# apollo3c register map
Vendor: Ambiq Micro; Series: Apollo; File version: 1.0
CPU: CM4 r1p0, little endian, MPU, FPU, 3 interrupt priority bits
Registers are 32-bit, read-write, reset 0x0 unless marked. A register's access mark holds for its fields unless they carry their own. Offsets are from the block's base; [hi:lo] are bit positions; lines under a group give offsets from that group; {n}, {i} and the like mark numbered series; 'fields as' and 'values as' point back to an identical list.

## GPIO (part 2 of 2) — General Purpose IO
Base 0x40010000
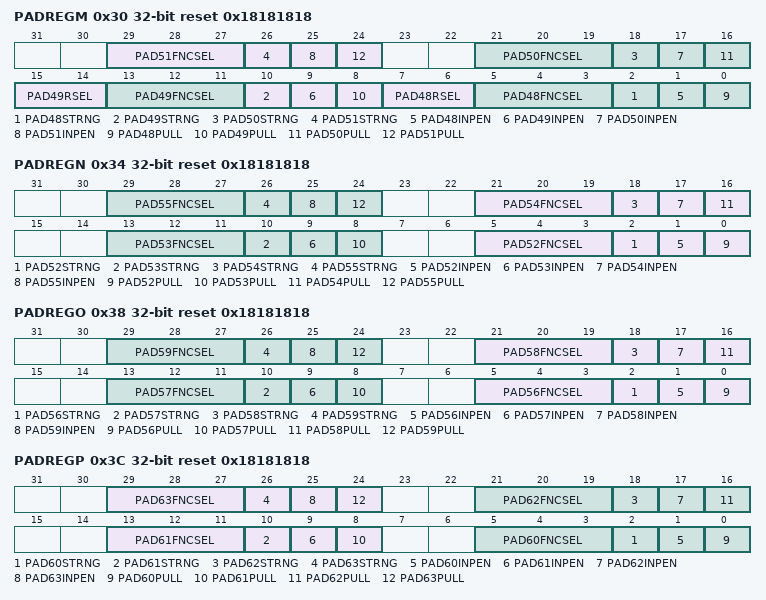
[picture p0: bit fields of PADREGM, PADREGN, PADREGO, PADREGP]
0x30 PADREGM reset 0x18181818 — Pad Configuration Register M (Pads 48-51)
  [29:27] PAD51FNCSEL — Pad 51 function select
    0=MSPI1_0 (Configure as the MSPI1 0 signal); 1=NCE51 (IOM/MSPI nCE group 51); 2=CT1 (CTIMER connection 1); 3=GPIO51 (Configure as GPIO51)
  [8n-382] PAD{n}STRNG (n=48..51) — Pad {n} drive strength
    0=LOW (Low drive strength); 1=HIGH (High drive strength)
  [8n-383] PAD{n}INPEN (n=48..51) — Pad {n} input enable
    0=DIS (Pad input disabled); 1=EN (Pad input enabled)
  [8n-384] PAD{n}PULL (n=48..51) — Pad {n} pullup enable
    0=DIS (Pullup disabled); 1=EN (Pullup enabled)
  [21:19] PAD50FNCSEL — Pad 50 function select
    0=SWO (Configure as the SWO output); 1=NCE50 (IOM/MSPI nCE group 50); 2=CT0 (CTIMER connection 0); 3=GPIO50 (Configure as GPIO50); 4=UART0TX (Configure as the UART0 TX output); 5=UART0RX (Configure as the UART0 RX input); 6=UART1TX (Configure as the UART1 TX output); 7=UART1RX (Configure as the UART1 RX input)
  [15:14] PAD49RSEL — Pad 49 pullup resistor selection.
    0=PULL1_5K (Pullup is ~1.5 KOhms); 1=PULL6K (Pullup is ~6 KOhms); 2=PULL12K (Pullup is ~12 KOhms); 3=PULL24K (Pullup is ~24 KOhms)
  [13:11] PAD49FNCSEL — Pad 49 function select
    0=UART0RX (Configure as the UART0 RX input signal); 1=NCE49 (IOM/MSPPI nCE group 49); 2=CT30 (CTIMER connection 30); 3=GPIO49 (Configure as GPIO49); 4=M5SDAWIR3 (Configure as the IOMSTR5 I2C SDA or SPI WIR3 signal); 5=M5MISO (Configure as the IOMSTR5 SPI MISO input signal)
  [7:6] PAD48RSEL — Pad 48 pullup resistor selection.
    values as PAD49RSEL
  [5:3] PAD48FNCSEL — Pad 48 function select
    0=UART0TX (Configure as the UART0 TX output signal); 1=NCE48 (IOM/MSPI nCE group 48); 2=CT28 (CTIMER conenction 28); 3=GPIO48 (Configure as GPIO48); 4=M5SCL (Configure as the IOMSTR5 I2C SCL clock I/O signal); 5=M5SCK (Configure as the IOMSTR5 SPI SCK output)
0x34 PADREGN reset 0x18181818 — Pad Configuration Register N (Pads 52-55)
  [8n-411:8n-413] PAD{n}FNCSEL (n=52..55) — Pad {n} function select
    0=MSPI1_{n-51} (Configure as the MSPI1 {n-51} signal); 1=NCE{n} (IOM/MSPI nCE group {n}); 2=CT{n-50} (CTIMER connection {n-50}); 3=GPIO{n} (Configure as GPIO{n})
  [8n-414] PAD{n}STRNG (n=52..55) — Pad {n} drive strength
    0=LOW (Low drive strength); 1=HIGH (High drive strength)
  [8n-415] PAD{n}INPEN (n=52..55) — Pad {n} input enable
    0=DIS (Pad input disabled); 1=EN (Pad input enabled)
  [8n-416] PAD{n}PULL (n=52..55) — Pad {n} pullup enable
    0=DIS (Pullup disabled); 1=EN (Pullup enabled)
0x38 PADREGO reset 0x18181818 — Pad Configuration Register O (Pads 56-59)
  [8n-443:8n-445] PAD{n}FNCSEL (n=56..59) — Pad {n} function select
    values as PADREGN.PAD52FNCSEL
  [8n-446] PAD{n}STRNG (n=56..59) — Pad {n} drive strength
    0=LOW (Low drive strength); 1=HIGH (High drive strength)
  [8n-447] PAD{n}INPEN (n=56..59) — Pad {n} input enable
    0=DIS (Pad input disabled); 1=EN (Pad input enabled)
  [8n-448] PAD{n}PULL (n=56..59) — Pad {n} pullup enable
    0=DIS (Pullup disabled); 1=EN (Pullup enabled)
0x3C PADREGP reset 0x18181818 — Pad Configuration Register P (Pads 60-63)
  [29:27] PAD63FNCSEL — Pad 63 function select
    0=SWO (Configure as the SWO output); 1=NCE63 (IOM/MSPI nCE group 63); 2=CT13 (CTIMER connection 13); 3=GPIO63 (Configure as GPIO63); 4=UART0TX (Configure as the UART0 TX output); 5=UART0RX (Configure as the UART0 RX input); 6=UART1TX (Configure as the UART1 TX output); 7=UART1RX (Configure as the UART1 RX input)
  [8n-478] PAD{n}STRNG (n=60..63) — Pad {n} drive strength
    0=LOW (Low drive strength); 1=HIGH (High drive strength)
  [8n-479] PAD{n}INPEN (n=60..63) — Pad {n} input enable
    0=DIS (Pad input disabled); 1=EN (Pad input enabled)
  [8n-480] PAD{n}PULL (n=60..63) — Pad {n} pullup enable
    0=DIS (Pullup disabled); 1=EN (Pullup enabled)
  [21:19] PAD62FNCSEL — Pad 62 function select
    0=SWO (Configure as the SWO output); 1=NCE62 (IOM/MSPI nCE group 62); 2=CT12 (CTIMER connection 12); 3=GPIO62 (Configure as GPIO62); 4=UA0CTS (Configure as the UART0 CTS input); 5=UA0RTS (Configure as the UART0 RTS output); 6=UA1CTS (Configure as the UART1 CTS input); 7=UA1RTS (Configure as the UART1 RTS output)
  [13:11] PAD61FNCSEL — Pad 61 function select
    0=SWO (Configure as the SWO output); 1=NCE61 (IOM/MSPI nCE group 61); 2=CT11 (CTIMER connection 11); 3=GPIO61 (Configure as GPIO61); 4=UART0TX (Configure as the UART0 TX output); 5=UART0RX (Configure as the UART0 RX input); 6=UART1TX (Configure as the UART1 TX output); 7=UART1RX (Configure as the UART1 RX input)
  [5:3] PAD60FNCSEL — Pad 60 function select
    0=MSPI1_9 (Configure as the MSPI1 9 signal); 1=NCE60 (IOM/MSPI nCE group 60); 2=CT10 (CTIMER connection 10); 3=GPIO60 (Configure as GPIO60)
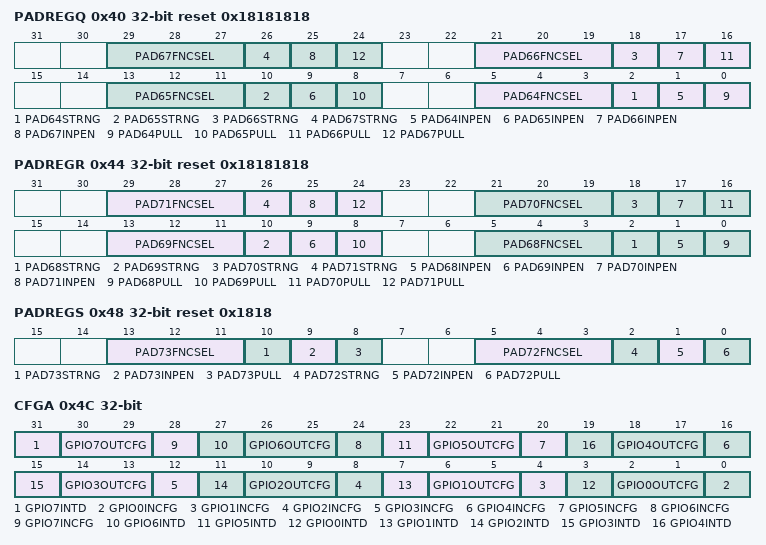
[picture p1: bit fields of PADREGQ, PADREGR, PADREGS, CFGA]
0x40 PADREGQ reset 0x18181818 — Pad Configuration Register Q (Pads 64-67)
  [8n-507:8n-509] PAD{n}FNCSEL (n=64..67) — Pad {n} function select
    0=MSPI2_{n-64} (Configure as the MSPI2 {n-64} signal); 1=NCE{n} (IOM/MSPI nCE group {n}); 2=CT{n-50} (CTIMER connection {n-50}); 3=GPIO{n} (Configure as GPIO{n})
  [8n-510] PAD{n}STRNG (n=64..67) — Pad {n} drive strength
    0=LOW (Low drive strength); 1=HIGH (High drive strength)
  [8n-511] PAD{n}INPEN (n=64..67) — Pad {n} input enable
    0=DIS (Pad input disabled); 1=EN (Pad input enabled)
  [8n-512] PAD{n}PULL (n=64..67) — Pad {n} pullup enable
    0=DIS (Pullup disabled); 1=EN (Pullup enabled)
0x44 PADREGR reset 0x18181818 — Pad Configuration Register R (Pads 68-71)
  [29:27] PAD71FNCSEL — Pad 71 function select
    0=SWO (Configure as the SWO output); 1=NCE71 (IOM/MSPI nCE group 71); 2=CT21 (CTIMER connection 21); 3=GPIO71 (Configure as GPIO71); 4=UART0TX (Configure as the UART0 TX output); 5=UART0RX (Configure as the UART0 RX input); 6=UART1TX (Configure as the UART1 TX output); 7=UART1RX (Configure as the UART1 RX input)
  [8n-542] PAD{n}STRNG (n=68..71) — Pad {n} drive strength
    0=LOW (Low drive strength); 1=HIGH (High drive strength)
  [8n-543] PAD{n}INPEN (n=68..71) — Pad {n} input enable
    0=DIS (Pad input disabled); 1=EN (Pad input enabled)
  [8n-544] PAD{n}PULL (n=68..71) — Pad {n} pullup enable
    0=DIS (Pullup disabled); 1=EN (Pullup enabled)
  [21:19] PAD70FNCSEL — Pad 70 function select
    0=SWO (Configure as the SWO output); 1=NCE70 (IOM/MSPI nCE group 70); 2=CT20 (CTIMER connection 20); 3=GPIO70 (Configure as GPIO70); 4=UART0TX (Configure as the UART0 TX output); 5=UART0RX (Configure as the UART0 RX input); 6=UART1TX (Configure as the UART1 TX output); 7=UART1RX (Configure as the UART1 RX input)
  [13:11] PAD69FNCSEL — Pad 69 function select
    0=SWO (Configure as the SWO output); 1=NCE69 (IOM/MSPI nCE group 69); 2=CT19 (CTIMER connection 19); 3=GPIO69 (Configure as GPIO69); 4=UART0TX (Configure as the UART0 TX output); 5=UART0RX (Configure as the UART0 RX input); 6=UART1TX (Configure as the UART1 TX output); 7=UART1RX (Configure as the UART1 RX input)
  [5:3] PAD68FNCSEL — Pad 68 function select
    0=MSPI2_4 (Configure as the MSPI2 4 signal); 1=NCE68 (IOM/MSPI nCE group 68); 2=CT18 (CTIMER connection 18); 3=GPIO68 (Configure as GPIO68)
0x48 PADREGS reset 0x1818 — Pad Configuration Register S (Pads 72-75)
  [13:11] PAD73FNCSEL — Pad 73 function select
    0=SWO (Configure as the SWO output); 1=NCE73 (IOM/MSPI nCE group 73); 2=CT23 (CTIMER connection 23); 3=GPIO73 (Configure as GPIO73); 4=UA0CTS (Configure as the UART0 CTS input); 5=UA0RTS (Configure as the UART0 RTS output); 6=UA1CTS (Configure as the UART1 CTS input); 7=UA1RTS (Configure as the UART1 RTS output)
  [10] PAD73STRNG — Pad 73 drive strength
    0=LOW (Low drive strength); 1=HIGH (High drive strength)
  [9] PAD73INPEN — Pad 73 input enable
    0=DIS (Pad input disabled); 1=EN (Pad input enabled)
  [8] PAD73PULL — Pad 73 pullup enable
    0=DIS (Pullup disabled); 1=EN (Pullup enabled)
  [5:3] PAD72FNCSEL — Pad 72 function select
    0=SWO (Configure as the SWO output); 1=NCE72 (IOM/MSPI nCE group 72); 2=CT22 (CTIMER connection 22); 3=GPIO72 (Configure as GPIO72); 4=UART0TX (Configure as the UART0 TX output); 5=UART0RX (Configure as the UART0 RX input); 6=UART1TX (Configure as the UART1 TX output); 7=UART1RX (Configure as the UART1 RX input)
  [2] PAD72STRNG — Pad 72 drive strength
    0=LOW (Low drive strength); 1=HIGH (High drive strength)
  [1] PAD72INPEN — Pad 72 input enable
    0=DIS (Pad input disabled); 1=EN (Pad input enabled)
  [0] PAD72PULL — Pad 72 pullup enable
    0=DIS (Pullup disabled); 1=EN (Pullup enabled)
0x4C CFGA — GPIO Configuration Register A (Pads 7-0)
  [31] GPIO7INTD — GPIO7 interrupt direction, nCE polarity.
    0=nCELOW (Applies when PAD7FNCSEL = NCE7 - nCE polarity active low); 1=nCEHIGH (Applies when PAD7FNCSEL = NCE7 - nCE polarity active high)
  [4n+2:4n+1] GPIO{n}OUTCFG (n=0..7) — GPIO{n} output configuration.
    0=DIS (Applies when PAD{n}FNCSEL = GPIO - Output disabled); 1=PUSHPULL (Applies when PAD{n}FNCSEL = GPIO - Output is push-pull); 2=OD (Applies when PAD{n}FNCSEL = GPIO - Output is open drain); 3=TS (Applies when PAD{n}FNCSEL = GPIO - Output is tri-state)
  [4n] GPIO{n}INCFG (n=0..7) — GPIO{n} input enable.
    0=READ (Read the GPIO pin data); 1=RDZERO (INTD = 0 - Readback will always be zero)
  [27] GPIO6INTD — GPIO6 interrupt direction, nCE polarity.
    0=INTDIS (Applies when GPIO6INCFG = 1 - No interrupt on GPIO transition); 1=INTBOTH (Applies when GPIO6INCFG = 1 - Interrupt on either low to high or high to low GPIO transition)
  [23] GPIO5INTD — GPIO5 interrupt direction, nCE polarity.
    0=INTDIS (Applies when GPIO5INCFG = 1 - No interrupt on GPIO transition); 1=INTBOTH (Applies when GPIO5INCFG = 1 - Interrupt on either low to high or high to low GPIO transition)
  [4n+3] GPIO{n}INTD (n=0..4) — GPIO{n} interrupt direction, nCE polarity.
    0=nCELOW (Applies when PAD{n}FNCSEL = NCE{n} - nCE polarity active low); 1=nCEHIGH (Applies when PAD{n}FNCSEL = NCE{n} - nCE polarity active high)
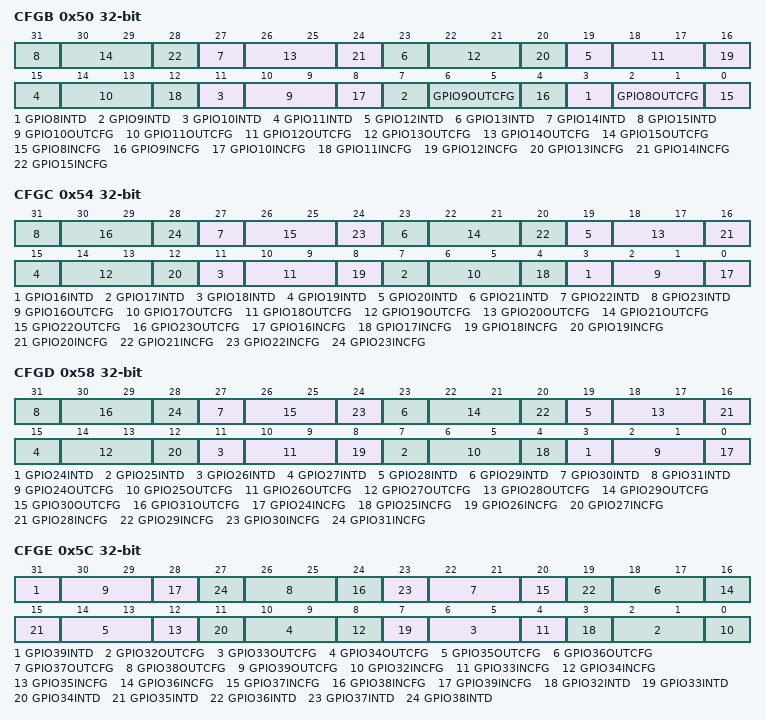
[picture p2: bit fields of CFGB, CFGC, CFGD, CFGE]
0x50 CFGB — GPIO Configuration Register B (Pads 15-8)
  [4n-29] GPIO{n}INTD (n=8..15) — GPIO{n} interrupt direction, nCE polarity.
    values as CFGA.GPIO0INTD
  [4n-30:4n-31] GPIO{n}OUTCFG (n=8..15) — GPIO{n} output configuration.
    values as CFGA.GPIO0OUTCFG
  [4n-32] GPIO{n}INCFG (n=8..15) — GPIO{n} input enable.
    values as CFGA.GPIO0INCFG
0x54 CFGC — GPIO Configuration Register C (Pads 23-16)
  [4n-61] GPIO{n}INTD (n=16..23) — GPIO{n} interrupt direction, nCE polarity.
    values as CFGA.GPIO0INTD
  [4n-62:4n-63] GPIO{n}OUTCFG (n=16..23) — GPIO{n} output configuration.
    values as CFGA.GPIO0OUTCFG
  [4n-64] GPIO{n}INCFG (n=16..23) — GPIO{n} input enable.
    values as CFGA.GPIO0INCFG
0x58 CFGD — GPIO Configuration Register D (Pads 31-24)
  [4n-93] GPIO{n}INTD (n=24..31) — GPIO{n} interrupt direction, nCE polarity.
    values as CFGA.GPIO0INTD
  [4n-94:4n-95] GPIO{n}OUTCFG (n=24..31) — GPIO{n} output configuration.
    values as CFGA.GPIO0OUTCFG
  [4n-96] GPIO{n}INCFG (n=24..31) — GPIO{n} input enable.
    values as CFGA.GPIO0INCFG
0x5C CFGE — GPIO Configuration Register E (Pads 39-32)
  [31] GPIO39INTD — GPIO39 interrupt direction, nCE polarity.
    0=INTDIS (Applies when GPIO39INCFG = 1 - No interrupt on GPIO transition); 1=INTBOTH (Applies when GPIO39INCFG = 1 - Interrupt on either low to high or high to low GPIO transition)
  [4n-126:4n-127] GPIO{n}OUTCFG (n=32..39) — GPIO{n} output configuration.
    values as CFGA.GPIO0OUTCFG
  [4n-128] GPIO{n}INCFG (n=32..39) — GPIO{n} input enable.
    values as CFGA.GPIO0INCFG
  [4n-125] GPIO{n}INTD (n=32..38) — GPIO{n} interrupt direction, nCE polarity.
    values as CFGA.GPIO0INTD
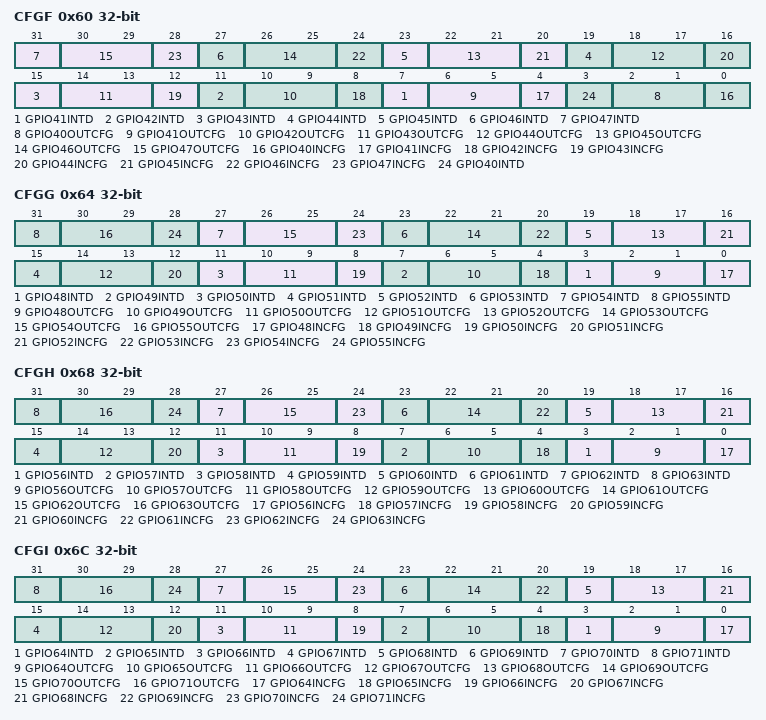
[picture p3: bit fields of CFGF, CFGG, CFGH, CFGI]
0x60 CFGF — GPIO Configuration Register F (Pads 47-40)
  [4n-157] GPIO{n}INTD (n=41..47) — GPIO{n} interrupt direction, nCE polarity.
    values as CFGA.GPIO0INTD
  [4n-158:4n-159] GPIO{n}OUTCFG (n=40..47) — GPIO{n} output configuration.
    values as CFGA.GPIO0OUTCFG
  [4n-160] GPIO{n}INCFG (n=40..47) — GPIO{n} input enable.
    values as CFGA.GPIO0INCFG
  [3] GPIO40INTD — GPIO40 interrupt direction, nCE polarity.
    0=INTDIS (Applies when GPIO40INCFG = 1 - No interrupt on GPIO transition); 1=INTBOTH (Applies when GPIO40INCFG = 1 - Interrupt on either low to high or high to low GPIO transition)
0x64 CFGG — GPIO Configuration Register G (Pads 55-48)
  [4n-189] GPIO{n}INTD (n=48..55) — GPIO{n} interrupt direction, nCE polarity.
    values as CFGA.GPIO0INTD
  [4n-190:4n-191] GPIO{n}OUTCFG (n=48..55) — GPIO{n} output configuration.
    values as CFGA.GPIO0OUTCFG
  [4n-192] GPIO{n}INCFG (n=48..55) — GPIO{n} input enable.
    values as CFGA.GPIO0INCFG
0x68 CFGH — GPIO Configuration Register H (Pads 63-56)
  [4n-221] GPIO{n}INTD (n=56..63) — GPIO{n} interrupt direction, nCE polarity.
    values as CFGA.GPIO0INTD
  [4n-222:4n-223] GPIO{n}OUTCFG (n=56..63) — GPIO{n} output configuration.
    values as CFGA.GPIO0OUTCFG
  [4n-224] GPIO{n}INCFG (n=56..63) — GPIO{n} input enable.
    values as CFGA.GPIO0INCFG
0x6C CFGI — GPIO Configuration Register I (Pads 71-64)
  [4n-253] GPIO{n}INTD (n=64..71) — GPIO{n} interrupt direction, nCE polarity.
    values as CFGA.GPIO0INTD
  [4n-254:4n-255] GPIO{n}OUTCFG (n=64..71) — GPIO{n} output configuration.
    values as CFGA.GPIO0OUTCFG
  [4n-256] GPIO{n}INCFG (n=64..71) — GPIO{n} input enable.
    values as CFGA.GPIO0INCFG
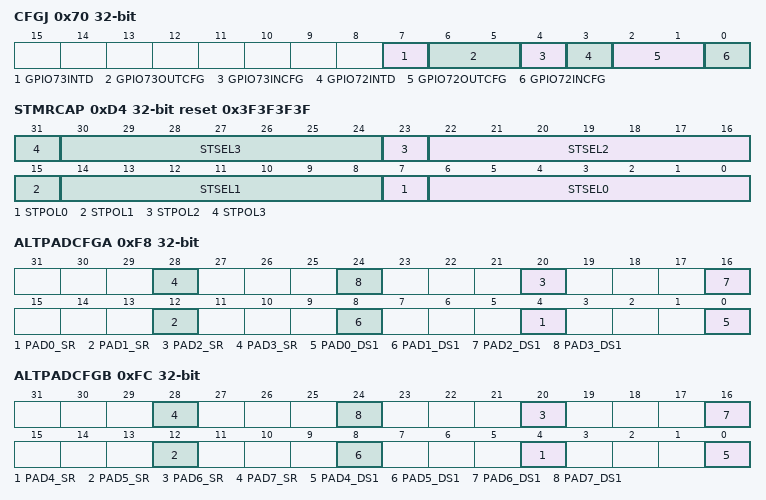
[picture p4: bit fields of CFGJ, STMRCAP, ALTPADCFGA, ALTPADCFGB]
0x70 CFGJ — GPIO Configuration Register J (Pads 79-72)
  [7] GPIO73INTD — GPIO73 interrupt direction, nCE polarity.
    0=nCELOW (Applies when PAD73FNCSEL = NCE73 - nCE polarity active low); 1=nCEHIGH (Applies when PAD73FNCSEL = NCE73 - nCE polarity active high)
  [6:5] GPIO73OUTCFG — GPIO73 output configuration.
    0=DIS (Applies when PAD73FNCSEL = GPIO - Output disabled); 1=PUSHPULL (Applies when PAD73FNCSEL = GPIO - Output is push-pull); 2=OD (Applies when PAD73FNCSEL = GPIO - Output is open drain); 3=TS (Applies when PAD73FNCSEL = GPIO - Output is tri-state)
  [4] GPIO73INCFG — GPIO73 input enable.
    values as CFGA.GPIO0INCFG
  [3] GPIO72INTD — GPIO72 interrupt direction, nCE polarity.
    0=nCELOW (Applies when PAD72FNCSEL = NCE72 - nCE polarity active low); 1=nCEHIGH (Applies when PAD72FNCSEL = NCE72 - nCE polarity active high)
  [2:1] GPIO72OUTCFG — GPIO72 output configuration.
    0=DIS (Applies when PAD72FNCSEL = GPIO - Output disabled); 1=PUSHPULL (Applies when PAD72FNCSEL = GPIO - Output is push-pull); 2=OD (Applies when PAD72FNCSEL = GPIO - Output is open drain); 3=TS (Applies when PAD72FNCSEL = GPIO - Output is tri-state)
  [0] GPIO72INCFG — GPIO72 input enable.
    values as CFGA.GPIO0INCFG
0x74 PADKEY — Key Register for all pad configuration registers
  [31:0] PADKEY — Key register value.
    115=Key
0x80 RDA — GPIO Input Register A
  [31:0] RDA — GPIO31-0 read data.
0x84 RDB — GPIO Input Register B
  [31:0] RDB — GPIO63-32 read data.
0x88 RDC — GPIO Input Register C
  [9:0] RDC — GPIO73-64 read data.
0x8C WTA — GPIO Output Register A
  [31:0] WTA — GPIO31-0 write data.
0x90 WTB — GPIO Output Register B
  [31:0] WTB — GPIO63-32 write data.
0x94 WTC — GPIO Output Register C
  [9:0] WTC — GPIO73-64 write data.
0x98 WTSA — GPIO Output Register A Set
  [31:0] WTSA — Set the GPIO31-0 write data.
0x9C WTSB — GPIO Output Register B Set
  [31:0] WTSB — Set the GPIO63-32 write data.
0xA0 WTSC — GPIO Output Register C Set
  [9:0] WTSC — Set the GPIO73-64 write data.
0xA4 WTCA — GPIO Output Register A Clear
  [31:0] WTCA — Clear the GPIO31-0 write data.
0xA8 WTCB — GPIO Output Register B Clear
  [31:0] WTCB — Clear the GPIO63-32 write data.
0xAC WTCC — GPIO Output Register C Clear
  [9:0] WTCB — Clear the GPIO73-64 write data.
0xB0 ENA — GPIO Enable Register A
  [31:0] ENA — GPIO31-0 output enables
0xB4 ENB — GPIO Enable Register B
  [31:0] ENB — GPIO63-32 output enables
0xB8 ENC — GPIO Enable Register C
  [9:0] ENC — GPIO73-64 output enables
0xBC ENSA — GPIO Enable Register A Set
  [31:0] ENSA — Set the GPIO31-0 output enables
0xC0 ENSB — GPIO Enable Register B Set
  [31:0] ENSB — Set the GPIO63-32 output enables
0xC4 ENSC — GPIO Enable Register C Set
  [9:0] ENSC — Set the GPIO73-64 output enables
0xC8 ENCA — GPIO Enable Register A Clear
  [31:0] ENCA — Clear the GPIO31-0 output enables
0xCC ENCB — GPIO Enable Register B Clear
  [31:0] ENCB — Clear the GPIO49-32 output enables
0xD0 ENCC — GPIO Enable Register C Clear
  [9:0] ENCC — Clear the GPIO73-64 output enables
0xD4 STMRCAP reset 0x3F3F3F3F — STIMER Capture Control
  [8n+7] STPOL{n} (n=0..3) — STIMER Capture {n} Polarity.
    0=CAPLH (Capture on low to high GPIO transition); 1=CAPHL (Capture on high to low GPIO transition)
  [8n+6:8n] STSEL{n} (n=0..3) — STIMER Capture {n} Select.
{0xD8+4i} IOM{i}IRQ reset 0x7F (i=0..3) — IOM{i} Flow Control IRQ Select
  [6:0] IOM{i}IRQ — IOMSTR{i} IRQ pad select.
0xE8 IOM4IRQ reset 0x3F — IOM4 Flow Control IRQ Select
  [6:0] IOM4IRQ — IOMSTR4 IRQ pad select.
0xEC IOM5IRQ reset 0x7F — IOM5 Flow Control IRQ Select
  [6:0] IOM5IRQ — IOMSTR5 IRQ pad select.
0xF0 BLEIFIRQ reset 0x7F — BLEIF Flow Control IRQ Select
  [6:0] BLEIFIRQ — BLEIF IRQ pad select.
0xF4 GPIOOBS — GPIO Observation Mode Sample register
  [15:0] OBS_DATA — Sample of the data output on the GPIO observation port. May have async sampling issues, as the data is not synronized to the read operation. Intended for debug purposes only
0xF8 ALTPADCFGA — Alternate Pad Configuration reg0 (Pads 3-0)
  [8n+4] PAD{n}_SR (n=0..3) — Pad 3 slew rate selection.
    1=SR_EN (Enables Slew rate control on pad)
  [8n] PAD{n}_DS1 (n=0..3) — Pad {n} high order drive strength selection. Used in conjunction with PAD{n}STRNG field to set the pad drive strength.
0xFC ALTPADCFGB — Alternate Pad Configuration reg0 (Pads 7-4)
  [8n-28] PAD{n}_SR (n=4..7) — Pad 7 slew rate selection.
    1=SR_EN (Enables Slew rate control on pad)
  [8n-32] PAD{n}_DS1 (n=4..7) — Pad {n} high order drive strength selection. Used in conjunction with PAD{n}STRNG field to set the pad drive strength.
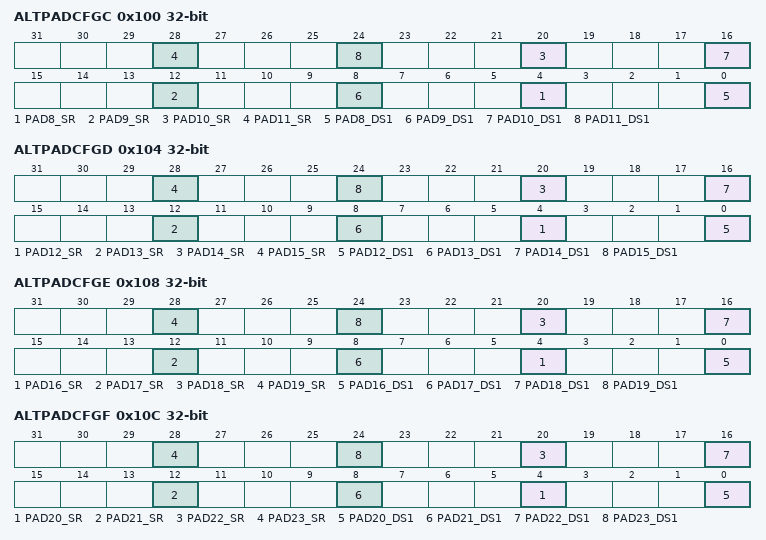
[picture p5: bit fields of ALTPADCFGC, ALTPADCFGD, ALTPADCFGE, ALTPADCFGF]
0x100 ALTPADCFGC — Alternate Pad Configuration reg0 (Pads 11-8)
  [8n-60] PAD{n}_SR (n=8..11) — Pad 11 slew rate selection.
    1=SR_EN (Enables Slew rate control on pad)
  [8n-64] PAD{n}_DS1 (n=8..11) — Pad {n} high order drive strength selection. Used in conjunction with PAD{n}STRNG field to set the pad drive strength.
0x104 ALTPADCFGD — Alternate Pad Configuration reg0 (Pads 15-12)
  [8n-92] PAD{n}_SR (n=12..15) — Pad 15 slew rate selection.
    1=SR_EN (Enables Slew rate control on pad)
  [8n-96] PAD{n}_DS1 (n=12..15) — Pad {n} high order drive strength selection. Used in conjunction with PAD{n}STRNG field to set the pad drive strength.
0x108 ALTPADCFGE — Alternate Pad Configuration reg0 (Pads 19-16)
  [8n-124] PAD{n}_SR (n=16..19) — Pad 19 slew rate selection.
    1=SR_EN (Enables Slew rate control on pad)
  [8n-128] PAD{n}_DS1 (n=16..19) — Pad {n} high order drive strength selection. Used in conjunction with PAD{n}STRNG field to set the pad drive strength.
0x10C ALTPADCFGF — Alternate Pad Configuration reg0 (Pads 23-20)
  [8n-156] PAD{n}_SR (n=20..23) — Pad 23 slew rate selection.
    1=SR_EN (Enables Slew rate control on pad)
  [8n-160] PAD{n}_DS1 (n=20..23) — Pad {n} high order drive strength selection. Used in conjunction with PAD{n}STRNG field to set the pad drive strength.
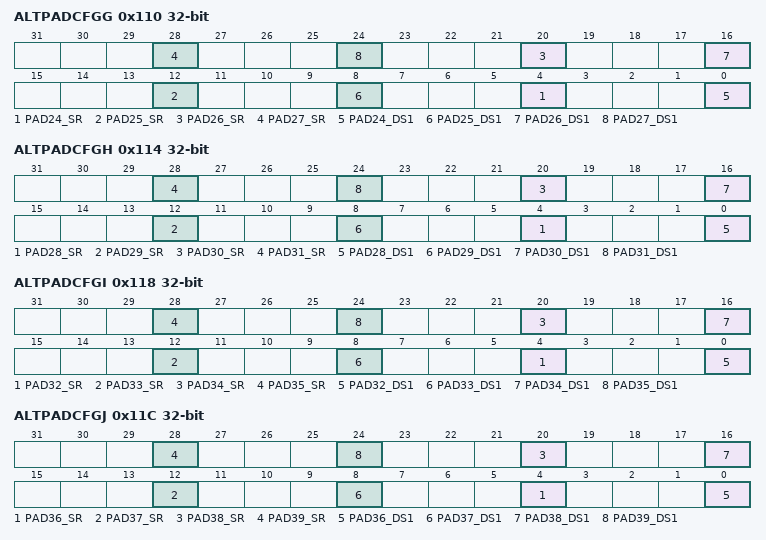
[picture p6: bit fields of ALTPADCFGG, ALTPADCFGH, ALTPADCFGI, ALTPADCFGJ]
0x110 ALTPADCFGG — Alternate Pad Configuration reg0 (Pads 27-24)
  [8n-188] PAD{n}_SR (n=24..27) — Pad 27 slew rate selection.
    1=SR_EN (Enables Slew rate control on pad)
  [8n-192] PAD{n}_DS1 (n=24..27) — Pad {n} high order drive strength selection. Used in conjunction with PAD{n}STRNG field to set the pad drive strength.
0x114 ALTPADCFGH — Alternate Pad Configuration reg0 (Pads 31-28)
  [8n-220] PAD{n}_SR (n=28..31) — Pad 31 slew rate selection.
    1=SR_EN (Enables Slew rate control on pad)
  [8n-224] PAD{n}_DS1 (n=28..31) — Pad {n} high order drive strength selection. Used in conjunction with PAD{n}STRNG field to set the pad drive strength.
0x118 ALTPADCFGI — Alternate Pad Configuration reg0 (Pads 35-32)
  [8n-252] PAD{n}_SR (n=32..35) — Pad 35 slew rate selection.
    1=SR_EN (Enables Slew rate control on pad)
  [8n-256] PAD{n}_DS1 (n=32..35) — Pad {n} high order drive strength selection. Used in conjunction with PAD{n}STRNG field to set the pad drive strength.
0x11C ALTPADCFGJ — Alternate Pad Configuration reg0 (Pads 39-36)
  [8n-284] PAD{n}_SR (n=36..39) — Pad 39 slew rate selection.
    1=SR_EN (Enables Slew rate control on pad)
  [8n-288] PAD{n}_DS1 (n=36..39) — Pad {n} high order drive strength selection. Used in conjunction with PAD{n}STRNG field to set the pad drive strength.
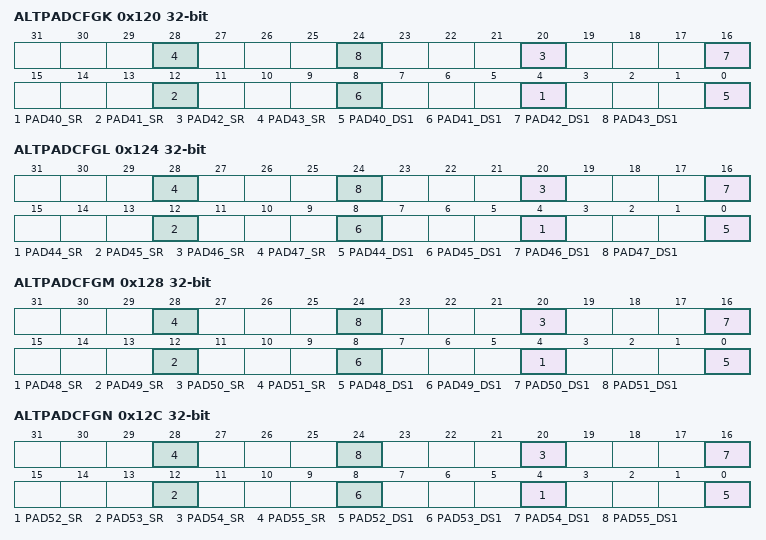
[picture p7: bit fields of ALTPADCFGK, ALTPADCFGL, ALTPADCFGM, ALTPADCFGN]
0x120 ALTPADCFGK — Alternate Pad Configuration reg0 (Pads 43-40)
  [8n-316] PAD{n}_SR (n=40..43) — Pad 43 slew rate selection.
    1=SR_EN (Enables Slew rate control on pad)
  [8n-320] PAD{n}_DS1 (n=40..43) — Pad {n} high order drive strength selection. Used in conjunction with PAD{n}STRNG field to set the pad drive strength.
0x124 ALTPADCFGL — Alternate Pad Configuration reg0 (Pads 47-44)
  [8n-348] PAD{n}_SR (n=44..47) — Pad 47 slew rate selection.
    1=SR_EN (Enables Slew rate control on pad)
  [8n-352] PAD{n}_DS1 (n=44..47) — Pad {n} high order drive strength selection. Used in conjunction with PAD{n}STRNG field to set the pad drive strength.
0x128 ALTPADCFGM — Alternate Pad Configuration reg0 (Pads 51-48)
  [8n-380] PAD{n}_SR (n=48..51) — Pad 51 slew rate selection.
    1=SR_EN (Enables Slew rate control on pad)
  [8n-384] PAD{n}_DS1 (n=48..51) — Pad {n} high order drive strength selection. Used in conjunction with PAD{n}STRNG field to set the pad drive strength.
0x12C ALTPADCFGN — Alternate Pad Configuration reg0 (Pads 55-52)
  [8n-412] PAD{n}_SR (n=52..55) — Pad 55 slew rate selection.
    1=SR_EN (Enables Slew rate control on pad)
  [8n-416] PAD{n}_DS1 (n=52..55) — Pad {n} high order drive strength selection. Used in conjunction with PAD{n}STRNG field to set the pad drive strength.
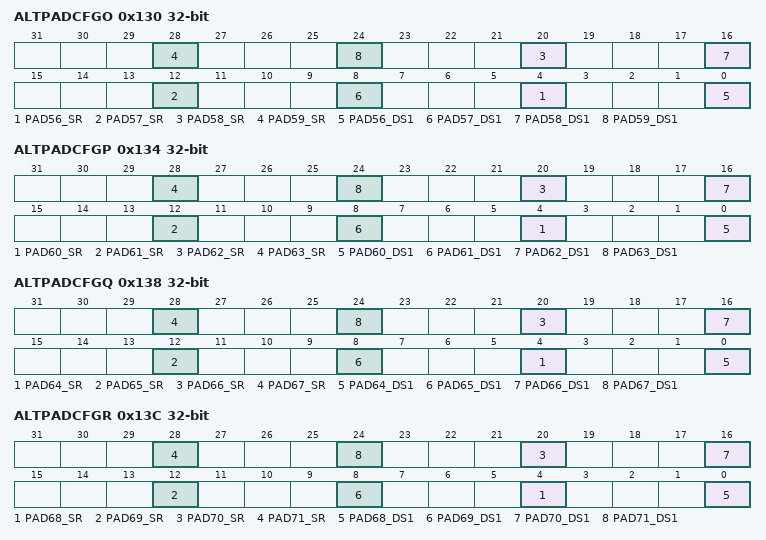
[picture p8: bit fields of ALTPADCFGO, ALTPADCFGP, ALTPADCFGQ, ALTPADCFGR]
0x130 ALTPADCFGO — Alternate Pad Configuration reg0 (Pads 59-56)
  [8n-444] PAD{n}_SR (n=56..59) — Pad 59 slew rate selection.
    1=SR_EN (Enables Slew rate control on pad)
  [8n-448] PAD{n}_DS1 (n=56..59) — Pad {n} high order drive strength selection. Used in conjunction with PAD{n}STRNG field to set the pad drive strength.
0x134 ALTPADCFGP — Alternate Pad Configuration reg0 (Pads 63-60)
  [8n-476] PAD{n}_SR (n=60..63) — Pad 63 slew rate selection.
    1=SR_EN (Enables Slew rate control on pad)
  [8n-480] PAD{n}_DS1 (n=60..63) — Pad {n} high order drive strength selection. Used in conjunction with PAD{n}STRNG field to set the pad drive strength.
0x138 ALTPADCFGQ — Alternate Pad Configuration reg0 (Pads 67-64)
  [8n-508] PAD{n}_SR (n=64..67) — Pad 67 slew rate selection.
    1=SR_EN (Enables Slew rate control on pad)
  [8n-512] PAD{n}_DS1 (n=64..67) — Pad {n} high order drive strength selection. Used in conjunction with PAD{n}STRNG field to set the pad drive strength.
0x13C ALTPADCFGR — Alternate Pad Configuration reg0 (Pads 71-68)
  [8n-540] PAD{n}_SR (n=68..71) — Pad 71 slew rate selection.
    1=SR_EN (Enables Slew rate control on pad)
  [8n-544] PAD{n}_DS1 (n=68..71) — Pad {n} high order drive strength selection. Used in conjunction with PAD{n}STRNG field to set the pad drive strength.
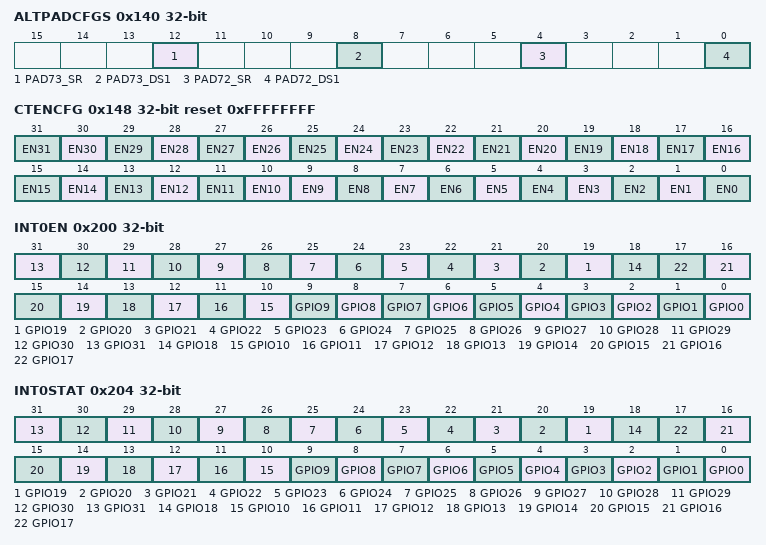
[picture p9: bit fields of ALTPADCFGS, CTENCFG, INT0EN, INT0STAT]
0x140 ALTPADCFGS — Alternate Pad Configuration reg0 (Pads 75-72)
  [12] PAD73_SR — Pad 75 slew rate selection.
    1=SR_EN (Enables Slew rate control on pad)
  [8] PAD73_DS1 — Pad 73 high order drive strength selection. Used in conjunction with PAD73STRNG field to set the pad drive strength.
  [4] PAD72_SR — Pad 75 slew rate selection.
    1=SR_EN (Enables Slew rate control on pad)
  [0] PAD72_DS1 — Pad 72 high order drive strength selection. Used in conjunction with PAD72STRNG field to set the pad drive strength.
0x144 SCDET reset 0x7F — SCARD Card Detect select
  [6:0] SCDET — SCARD card detect pad select.
0x148 CTENCFG reset 0xFFFFFFFF — Counter/Timer Enable Config
  [n] EN{n} (n=10..31) — CT{n} Enable
    1=DIS (Disable CT{n} for output); 0=EN (Enable CT{n} for output)
  [9] EN9 — CT9 Enable
    0=DIS (Disable CT9 for output)
  [n] EN{n} (n=0..8) — CT{n} Enable
    values as EN10
0x200 INT0EN — GPIO Interrupt Registers 31-0: Enable
  [n] GPIO{n} (n=19..31) — GPIO{n} interrupt.
  [18] GPIO18 — GPIO18interrupt.
  [n] GPIO{n} (n=0..17) — GPIO{n} interrupt.
0x204 INT0STAT — GPIO Interrupt Registers 31-0: Status
  fields as INT0EN
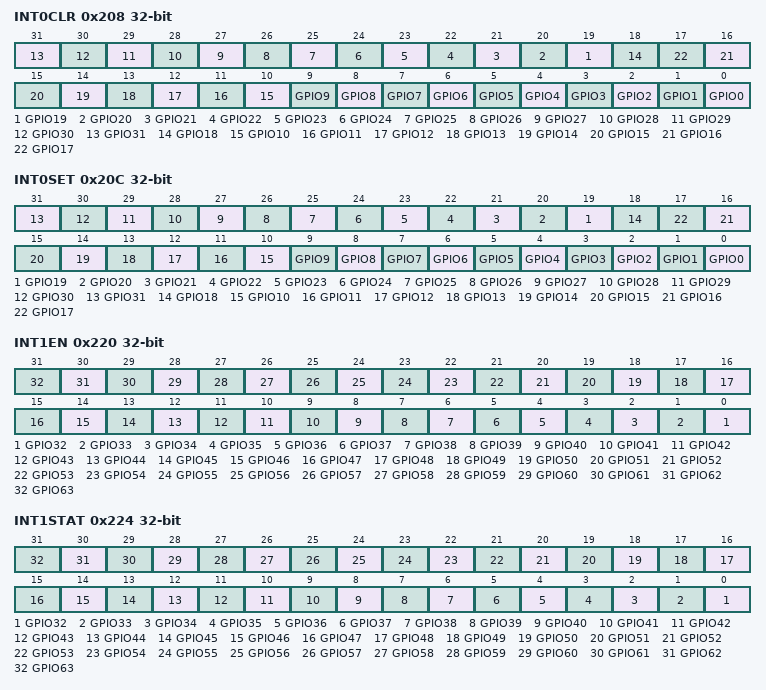
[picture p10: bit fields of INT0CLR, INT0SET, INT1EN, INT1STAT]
0x208 INT0CLR — GPIO Interrupt Registers 31-0: Clear
  fields as INT0EN
0x20C INT0SET — GPIO Interrupt Registers 31-0: Set
  fields as INT0EN
0x220 INT1EN — GPIO Interrupt Registers 63-32: Enable
  [n-32] GPIO{n} (n=32..63) — GPIO{n} interrupt.
0x224 INT1STAT — GPIO Interrupt Registers 63-32: Status
  [n-32] GPIO{n} (n=32..63) — GPIO{n} interrupt.
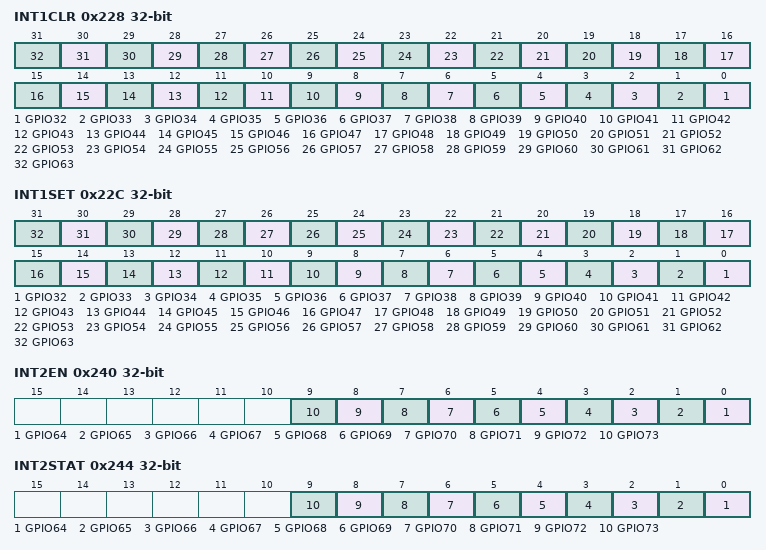
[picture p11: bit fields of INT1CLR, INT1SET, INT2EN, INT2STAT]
0x228 INT1CLR — GPIO Interrupt Registers 63-32: Clear
  [n-32] GPIO{n} (n=32..63) — GPIO{n} interrupt.
0x22C INT1SET — GPIO Interrupt Registers 63-32: Set
  [n-32] GPIO{n} (n=32..63) — GPIO{n} interrupt.
0x240 INT2EN — GPIO Interrupt Registers 73-64: Enable
  [n-64] GPIO{n} (n=64..73) — GPIO{n} interrupt.
0x244 INT2STAT — GPIO Interrupt Registers 73-64: Status
  [n-64] GPIO{n} (n=64..73) — GPIO{n} interrupt.
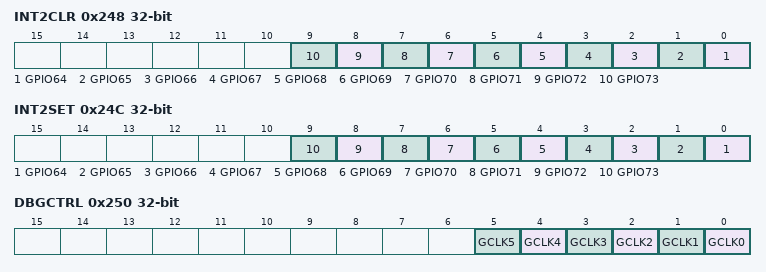
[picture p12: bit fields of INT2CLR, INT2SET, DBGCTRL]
0x248 INT2CLR — GPIO Interrupt Registers 73-64: Clear
  [n-64] GPIO{n} (n=64..73) — GPIO{n} interrupt.
0x24C INT2SET — GPIO Interrupt Registers 73-64: Set
  [n-64] GPIO{n} (n=64..73) — GPIO{n} interrupt.
0x250 DBGCTRL — Debug Control
  [n] GCLK{n} (n=0..5) — Gate IOM{n} CLK in SPI mode, allowing external input clock
